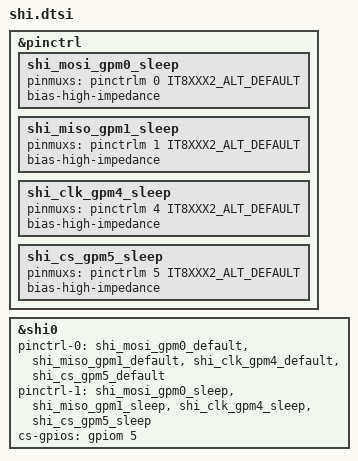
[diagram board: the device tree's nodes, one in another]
/* Copyright 2023 The ChromiumOS Authors
 * Use of this source code is governed by a BSD-style license that can be
 * found in the LICENSE file.
 */

#include <ite/it8xxx2-pinctrl-map.dtsi>
&pinctrl {
	shi_mosi_gpm0_sleep: shi_mosi_gpm0_sleep {
		pinmuxs = <&pinctrlm 0 IT8XXX2_ALT_DEFAULT>;
		bias-high-impedance;
	};

	shi_miso_gpm1_sleep: shi_miso_gpm1_sleep {
		pinmuxs = <&pinctrlm 1 IT8XXX2_ALT_DEFAULT>;
		bias-high-impedance;
	};

	shi_clk_gpm4_sleep: shi_clk_gpm4_sleep {
		pinmuxs = <&pinctrlm 4 IT8XXX2_ALT_DEFAULT>;
		bias-high-impedance;
	};

	shi_cs_gpm5_sleep: shi_cs_gpm5_sleep {
		pinmuxs = <&pinctrlm 5 IT8XXX2_ALT_DEFAULT>;
		bias-high-impedance;
	};
};

&shi0 {
	status = "okay";
	pinctrl-0 = <&shi_mosi_gpm0_default &shi_miso_gpm1_default
		     &shi_clk_gpm4_default &shi_cs_gpm5_default>;
	pinctrl-1 = <&shi_mosi_gpm0_sleep &shi_miso_gpm1_sleep
			 &shi_clk_gpm4_sleep &shi_cs_gpm5_sleep>;
	pinctrl-names = "default", "sleep";
	/* unused but needed by dt binding */
	cs-gpios = <&gpiom 5 GPIO_VOLTAGE_1P8>;
};
